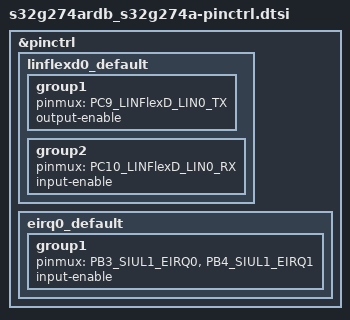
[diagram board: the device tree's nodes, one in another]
/*
 * Copyright 2025 NXP
 *
 * SPDX-License-Identifier: Apache-2.0
 */

#include <nxp/s32/S32G274ARDB-pinctrl.h>

&pinctrl {
	linflexd0_default: linflexd0_default {
		group1 {
			pinmux = <PC9_LINFlexD_LIN0_TX>;
			output-enable;
		};

		group2 {
			pinmux = <PC10_LINFlexD_LIN0_RX>;
			input-enable;
		};
	};
	eirq0_default: eirq0_default {
		group1 {
			pinmux = <PB3_SIUL1_EIRQ0>, <PB4_SIUL1_EIRQ1>;
			input-enable;
		};
	};

#if 0
	flexcan0_default: flexcan0_default {
		group1 {
			pinmux = <PB1_FlexCAN_CAN0_TX>;
			output-enable;
		};

		group2 {
			pinmux = <PB2_FlexCAN_CAN0_RX>;
			input-enable;
		};
	};
#endif
};
